# CY8C4245AXI_483 register map
File version: 0.1
PSoC 4200
Registers are 32-bit, read-write, no defined reset value unless marked. A register's access mark holds for its fields unless they carry their own. Offsets are from the block's base; lines under a group give offsets from that group; [hi:lo] are bit positions; {n}, {i} and the like mark numbered series; 'fields as' and 'values as' point back to an identical list; <NAME> marks a mode.

## Memory map
0x00000000 IDAC_Iref — IDAC
0x00000000 ADC_SAR_Seq_1 — Sequencing SAR ADC
0x00000000 UART_BCP — Serial Communication Block
0x00000000 Timer_1
0x00000000 LPComp_OC — Low Power Comparator
0x00000000 Counter_Spd
0x00000000 PWM_Drive
0x00000000 Hall_Error
0x00000000 CtrlReg_Dir
0x00000000 CtrlReg_PWMOut

## IDAC_Iref — IDAC
Base 0x00000000
0x40080004 CSD_IDAC_POLARITY
0x40080008 CSD_IDAC
0x4008FF00 CSD_TRIM1 — CSD IDAC TRIM1
0x4008FF04 CSD_TRIM2 — CSD IDAC TRIM2

## Timer_1
Base 0x00000000
0x400F0002 Timer_1_COUNTER 16-bit — UDB.A0 - Current Down Counter Value
0x400F0022 Timer_1_PERIOD 16-bit — UDB.D0 - Assigned Period
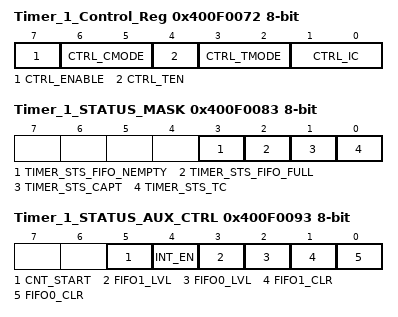
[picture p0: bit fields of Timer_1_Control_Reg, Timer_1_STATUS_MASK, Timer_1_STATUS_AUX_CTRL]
0x400F0072 Timer_1_Control_Reg 8-bit — UDB Control Register - Assigned Control Register Value
  [7] CTRL_ENABLE — Enable the Timer
  [6:5] CTRL_CMODE — Capture Mode
  [4] CTRL_TEN — Trigger Enable Bit
  [3:2] CTRL_TMODE — Trigger Mode
  [1:0] CTRL_IC — Interrupt Count
0x400F0083 Timer_1_STATUS_MASK 8-bit — UDB Status bits Interrupt Mask Enable Register
  [3] TIMER_STS_FIFO_NEMPTY ro — FIFO Empty status
  [2] TIMER_STS_FIFO_FULL ro — FIFO Full Status
  [1] TIMER_STS_CAPT ro — Enables the Interrupt on Capture
  [0] TIMER_STS_TC ro — Enables the Interrupt on TC
0x400F0093 Timer_1_STATUS_AUX_CTRL 8-bit — UDB Auxilliary Control Register
  [5] CNT_START — FIFO0 clear
    0=E_CNT_START0 (Disable counter); 1=E_CNT_START1 (Enable counter)
  [4] INT_EN
    0=E_INT_EN0 (Interrupt disabled); 1=E_INT_EN1 (Interrupt enabled)
  [3] FIFO1_LVL — FIFO level
    0=E_FIFO_LVL_0 (FIFO LVL: input mode: FIFO not full; output mode: FIFO not empty); 1=E_FIFO_LVL_1 (FIFO LVL: input mode: FIFO at least 1/2 empty; output mode: FIFO at least 1/2 full)
  [2] FIFO0_LVL — FIFO level
    values as FIFO1_LVL
  [1] FIFO1_CLR — FIFO1 clear
    0=E_FIFO_CLR_0 (Normal FIFO operation); 1=E_FIFO_CLR_1 (Clear FIFO state)
  [0] FIFO0_CLR — FIFO0 clear
    values as FIFO1_CLR

## LPComp_OC — Low Power Comparator
Base 0x00000000
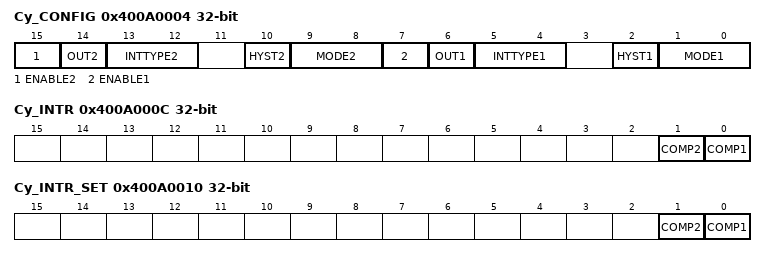
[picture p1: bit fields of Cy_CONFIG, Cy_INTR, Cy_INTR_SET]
0x400A0004 Cy_CONFIG — LPCOMP configuration
  [15] ENABLE2 — Enable comparator #2
    0=DISABLE (Comparator disabled); 1=ENABLE (Comparator enabled)
  [14] OUT2 ro — Current output value of the comparator #2
  [13:12] INTTYPE2 — Sets which edge will trigger an IRQ for the comparator #2
    0=DISABLE (Disabled); 1=RISING (Rising edge); 2=FALLING (Falling edge); 3=BOTH (Both rising and falling edges)
  [10] HYST2 — Selects hysteresis (10mV) for the comparator #2
    0=ENABLE (Hysteresis enabled); 1=DISABLE (Hysteresis disabled)
  [9:8] MODE2 — Selects speed for the comparator #2
    0=MED (Medium speed); 1=FAST (Fast speed); 2=SLOW (Slow speed)
  [7] ENABLE1 — Enable comparator #1
    values as ENABLE2
  [6] OUT1 ro — Current output value of the comparator
  [5:4] INTTYPE1 — Sets which edge will trigger an IRQ for the comparator #1
    values as INTTYPE2
  [2] HYST1 — Selects hysteresis (10mV) for the comparator #1
    values as HYST2
  [1:0] MODE1 — Selects speed for the comparator #1
    values as MODE2
0x400A000C Cy_INTR — LPCOMP interrupt
  [1] COMP2 — Comparator #2 Interrupt: hardware sets this interrupt when comparator 0 triggers. Write with '1' to clear bit.
  [0] COMP1 — Comparator #1 Interrupt: hardware sets this interrupt when comparator 0 triggers. Write with '1' to clear bit.
0x400A0010 Cy_INTR_SET — LPCOMP interrupt set register
  [1] COMP2 — Write with '1' to set corresponding bit in interrupt request register.
  [0] COMP1 — Write with '1' to set corresponding bit in interrupt request register.
0x400AFF00 Cy_TRIM_A — LPCOMP trim A
0x400AFF04 Cy_TRIM_B — LPCOMP trim B
